# CBASS_CBASS_QOS_45D20000h register map
Vendor: Texas Instruments
Peripheral module from a debugger description file (folder am62L).
Registers are 32-bit, read-write, reset 0x7000 unless marked. A register's access mark holds for its fields unless they carry their own. Offsets are as the file gives them; lines under a group give offsets from that group; [hi:lo] are bit positions; {n}, {i} and the like mark numbered series; 'fields as' and 'values as' point back to an identical list; <NAME> marks a mode.

## CBASS_QOS
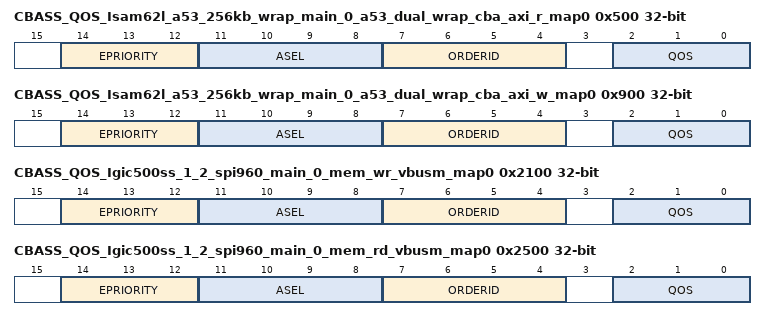
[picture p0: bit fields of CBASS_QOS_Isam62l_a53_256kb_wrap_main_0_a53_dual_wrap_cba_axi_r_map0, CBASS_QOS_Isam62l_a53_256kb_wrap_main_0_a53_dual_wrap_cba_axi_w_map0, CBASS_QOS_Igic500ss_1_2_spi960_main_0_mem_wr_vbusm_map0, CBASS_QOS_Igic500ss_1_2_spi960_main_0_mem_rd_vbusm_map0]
0x500 CBASS_QOS_Isam62l_a53_256kb_wrap_main_0_a53_dual_wrap_cba_axi_r_map0 — The Map Register defines the fields for the initiator A53SS0 Read Port per channel
  [14:12] EPRIORITY — epriority signal for channel N.This is the strict priority arbitration priority at the destination Reset Source: domain_default_rst_mod_g_rst_n
  [11:8] ASEL — Only used for PCIe, and cache coherency with A53 ACP. So traffic to MSRAM or DDR with asel set to below values will be routed via A53 cache controller. ASEL=0 | normalASEL=1 | PCIe address space for the entire addressASEL=14 | W | cause L2 cache allocation: for cache warming featureASEL=14 | R | does not cause L2 cache allocationASEL=15 | R/W | does not cause L2 cache allocation Reset Source: domain_default_rst_mod_g_rst_n
  [7:4] ORDERID — orderid signal for channel N.Selects to route for load balancing (0-7 uses one route, 8-15 another).Also used by DDR4/LPDDR4 re-ordering to maximize throughput. Order of transactions is only guaranteed with the same orderid Reset Source: domain_default_rst_mod_g_rst_n
  [2:0] QOS — qos signal for channel N. Reset Source: domain_default_rst_mod_g_rst_n
0x900 CBASS_QOS_Isam62l_a53_256kb_wrap_main_0_a53_dual_wrap_cba_axi_w_map0 — The Map Register defines the fields for the initiator A53SS0 Write Port per channel
  fields as CBASS_QOS_Isam62l_a53_256kb_wrap_main_0_a53_dual_wrap_cba_axi_r_map0
0x2100 CBASS_QOS_Igic500ss_1_2_spi960_main_0_mem_wr_vbusm_map0 — The Map Register defines the fields for the initiator GICSS0 Write Port per channel
  fields as CBASS_QOS_Isam62l_a53_256kb_wrap_main_0_a53_dual_wrap_cba_axi_r_map0
0x2500 CBASS_QOS_Igic500ss_1_2_spi960_main_0_mem_rd_vbusm_map0 — The Map Register defines the fields for the initiator GICSS0 Read Port per channel
  fields as CBASS_QOS_Isam62l_a53_256kb_wrap_main_0_a53_dual_wrap_cba_axi_r_map0
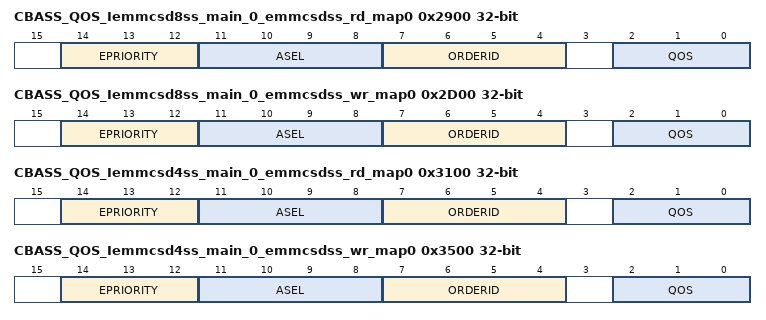
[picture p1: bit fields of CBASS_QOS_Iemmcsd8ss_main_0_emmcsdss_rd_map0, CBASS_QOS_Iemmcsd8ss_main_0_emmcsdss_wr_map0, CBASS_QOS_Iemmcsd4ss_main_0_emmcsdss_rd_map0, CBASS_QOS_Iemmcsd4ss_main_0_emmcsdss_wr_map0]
0x2900 CBASS_QOS_Iemmcsd8ss_main_0_emmcsdss_rd_map0 — The Map Register defines the fields for the initiator MMCSD0 Read Port per channel
  fields as CBASS_QOS_Isam62l_a53_256kb_wrap_main_0_a53_dual_wrap_cba_axi_r_map0
0x2D00 CBASS_QOS_Iemmcsd8ss_main_0_emmcsdss_wr_map0 — The Map Register defines the fields for the initiator MMCSD0 Write Port per channel
  fields as CBASS_QOS_Isam62l_a53_256kb_wrap_main_0_a53_dual_wrap_cba_axi_r_map0
0x3100 CBASS_QOS_Iemmcsd4ss_main_0_emmcsdss_rd_map0 — The Map Register defines the fields for the initiator MMCSD1 Read Port per channel
  fields as CBASS_QOS_Isam62l_a53_256kb_wrap_main_0_a53_dual_wrap_cba_axi_r_map0
0x3500 CBASS_QOS_Iemmcsd4ss_main_0_emmcsdss_wr_map0 — The Map Register defines the fields for the initiator MMCSD1 Write Port per channel
  fields as CBASS_QOS_Isam62l_a53_256kb_wrap_main_0_a53_dual_wrap_cba_axi_r_map0
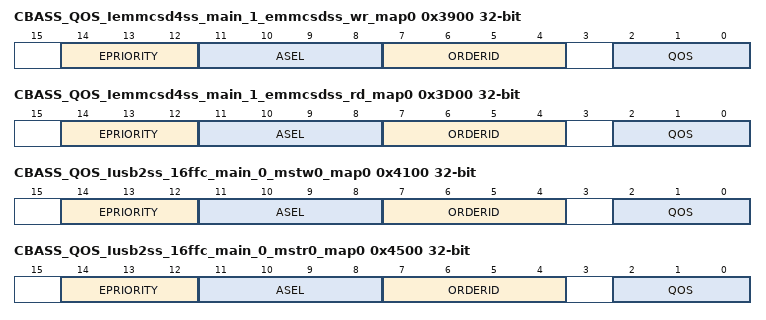
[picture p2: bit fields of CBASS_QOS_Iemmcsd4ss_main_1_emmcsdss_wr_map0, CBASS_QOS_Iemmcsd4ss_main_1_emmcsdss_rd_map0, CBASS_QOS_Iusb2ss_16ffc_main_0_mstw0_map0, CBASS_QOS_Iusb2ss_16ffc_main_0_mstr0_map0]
0x3900 CBASS_QOS_Iemmcsd4ss_main_1_emmcsdss_wr_map0 — The Map Register defines the fields for the initiator MMCSD2 Write Port per channel
  fields as CBASS_QOS_Isam62l_a53_256kb_wrap_main_0_a53_dual_wrap_cba_axi_r_map0
0x3D00 CBASS_QOS_Iemmcsd4ss_main_1_emmcsdss_rd_map0 — The Map Register defines the fields for the initiator MMCSD2 Read Port per channel
  fields as CBASS_QOS_Isam62l_a53_256kb_wrap_main_0_a53_dual_wrap_cba_axi_r_map0
0x4100 CBASS_QOS_Iusb2ss_16ffc_main_0_mstw0_map0 — The Map Register defines the fields for the initiator USB0 Write Port per channel
  fields as CBASS_QOS_Isam62l_a53_256kb_wrap_main_0_a53_dual_wrap_cba_axi_r_map0
0x4500 CBASS_QOS_Iusb2ss_16ffc_main_0_mstr0_map0 — The Map Register defines the fields for the initiator USB0 Read Port per channel
  fields as CBASS_QOS_Isam62l_a53_256kb_wrap_main_0_a53_dual_wrap_cba_axi_r_map0
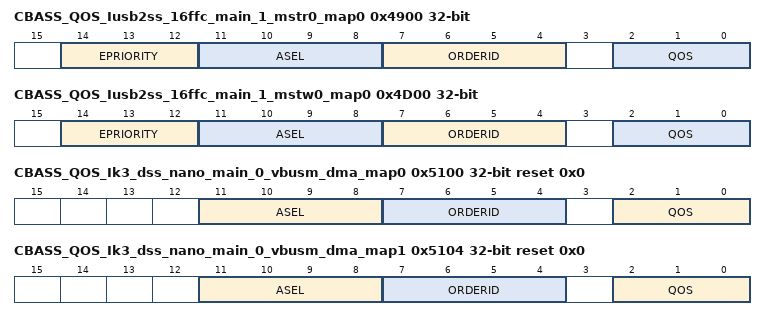
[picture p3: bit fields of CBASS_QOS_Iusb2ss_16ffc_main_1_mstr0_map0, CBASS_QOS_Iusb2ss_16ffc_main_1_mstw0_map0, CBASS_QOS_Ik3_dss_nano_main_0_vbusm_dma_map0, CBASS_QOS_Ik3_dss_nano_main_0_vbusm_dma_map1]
0x4900 CBASS_QOS_Iusb2ss_16ffc_main_1_mstr0_map0 — The Map Register defines the fields for the initiator USB1 Read Port per channel
  fields as CBASS_QOS_Isam62l_a53_256kb_wrap_main_0_a53_dual_wrap_cba_axi_r_map0
0x4D00 CBASS_QOS_Iusb2ss_16ffc_main_1_mstw0_map0 — The Map Register defines the fields for the initiator USB1 Write Port per channel
  fields as CBASS_QOS_Isam62l_a53_256kb_wrap_main_0_a53_dual_wrap_cba_axi_r_map0
0x5100 CBASS_QOS_Ik3_dss_nano_main_0_vbusm_dma_map0 reset 0x0 — The Map Register defines the fields for the initiator DSS0 Port per channel
  [11:8] ASEL — Only used for PCIe, and cache coherency with A53 ACP. So traffic to MSRAM or DDR with asel set to below values will be routed via A53 cache controller. ASEL=0 | normalASEL=1 | PCIe address space for the entire addressASEL=14 | W | cause L2 cache allocation: for cache warming featureASEL=14 | R | does not cause L2 cache allocationASEL=15 | R/W | does not cause L2 cache allocation Reset Source: domain_default_rst_mod_g_rst_n
  [7:4] ORDERID — orderid signal for channel N.Selects to route for load balancing (0-7 uses one route, 8-15 another).Also used by DDR4/LPDDR4 re-ordering to maximize throughput. Order of transactions is only guaranteed with the same orderid Reset Source: domain_default_rst_mod_g_rst_n
  [2:0] QOS — qos signal for channel N. Reset Source: domain_default_rst_mod_g_rst_n
0x5104 CBASS_QOS_Ik3_dss_nano_main_0_vbusm_dma_map1 reset 0x0 — The Map Register defines the fields for the initiator DSS0 Port per channel
  fields as CBASS_QOS_Ik3_dss_nano_main_0_vbusm_dma_map0
